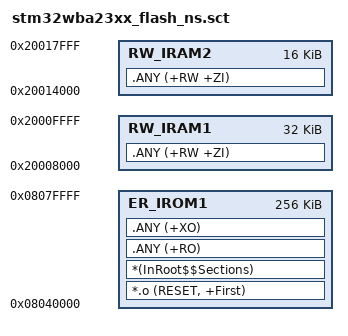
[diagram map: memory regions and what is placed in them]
; *************************************************************
; *** Scatter-Loading Description File generated by uVision ***
; *************************************************************

LR_IROM1 0x08040000 0x00040000  {    ; load region size_region
  ER_IROM1 0x08040000 0x00040000  {  ; load address = execution address
   *.o (RESET, +First)
   *(InRoot$$Sections)
   .ANY (+RO)
   .ANY (+XO)
  }
  RW_IRAM1 0x20008000 0x00008000  {  ; RW data
   .ANY (+RW +ZI)
  }
  RW_IRAM2 0x20014000 0x00004000  {  ; RW data
   .ANY (+RW +ZI)
  }
}

